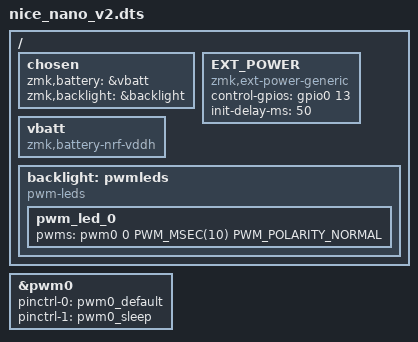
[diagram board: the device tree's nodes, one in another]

/dts-v1/;
#include "nice_nano_v2-pinctrl.dtsi"
#include "nice_nano.dtsi"


/ {
    chosen {
        zmk,battery = &vbatt;
    };

    // Node name must match original "EXT_POWER" label to preserve user settings.
    EXT_POWER {
        compatible = "zmk,ext-power-generic";
        control-gpios = <&gpio0 13 GPIO_ACTIVE_HIGH>;
        init-delay-ms = <50>;
    };

    vbatt: vbatt {
        compatible = "zmk,battery-nrf-vddh";
    };
};



&pwm0 {
    status = "okay";
    pinctrl-0 = <&pwm0_default>;
    pinctrl-1 = <&pwm0_sleep>;
    pinctrl-names = "default", "sleep";
};


/ {
    backlight: pwmleds {
        compatible = "pwm-leds";
        pwm_led_0 {
            pwms = <&pwm0 0 PWM_MSEC(10) PWM_POLARITY_NORMAL>;
        };
    };
};


/ {
    chosen {
        zmk,backlight = &backlight;
    };
};
